# CM41x_M4 register map
Vendor: Analog Devices; Series: CM41x_M4; File version: 1p0
CPU: CM4 r0p1, little endian, MPU, FPU, 4 interrupt priority bits
Registers are 32-bit, read-write, reset 0x0 unless marked. A register's access mark holds for its fields unless they carry their own. Offsets are from the block's base; [hi:lo] are bit positions; lines under a group give offsets from that group; {n}, {i} and the like mark numbered series; 'fields as' and 'values as' point back to an identical list.

## SEC1 — System Event Controller
Base 0x40010000
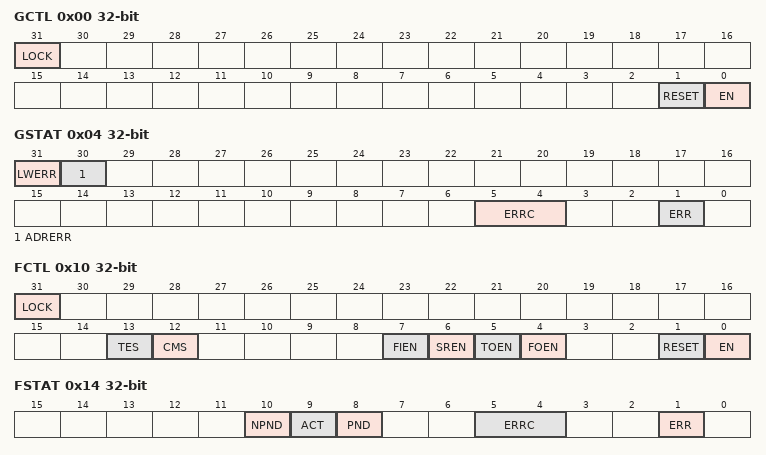
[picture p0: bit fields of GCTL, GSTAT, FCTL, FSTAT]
0x00 GCTL — Global Control Register
  [31] LOCK
    0=UNLOCK; 1=LOCK
  [1] RESET
    0=NO_RESET (No Action); 1=RESET
  [0] EN — Enable
    0=DIS (Disable); 1=EN (Enable)
0x04 GSTAT — Global Status Register
  [31] LWERR — Lock Write Error
    0=NO_LWERR (No Error); 1=LWERR (Error Occurred)
  [30] ADRERR — Address Error
    0=NO_ADRERR (No Error); 1=ADRERR (Error Occurred)
  [5:4] ERRC ro — Error Cause
    0=SFIERR (SFI Error); 2=SSIERR (SSI Error)
  [1] ERR — Error
    0=NO_ERR (No Error); 1=ERR (Error Occurred)
0x08 RAISE — Global Raise Register
  [7:0] SID range 0x00000000..0x000000FF — Source ID
0x10 FCTL — Fault Control Register
  [31] LOCK
    0=UNLOCK; 1=LOCK
  [13] TES — Trigger Event Select
    0=FLTACT_MODE (Fault Active Mode); 1=FLTPND_MODE (Fault Pending Mode)
  [12] CMS — COP Mode Select
    0=FLT_MODE (Fault Mode); 1=COP_MODE
  [7] FIEN — Fault Input Enable
    0=FLTIN_DIS (Disable); 1=FLTIN_EN (Enable)
  [6] SREN — System Reset Enable
    0=SYSRST_DIS (Disable); 1=SYSRST_EN (Enable)
  [5] TOEN — Trigger Output Enable
    0=TRGOUT_DIS (Disable); 1=TRGOUT_EN (Enable)
  [4] FOEN — Fault Output Enable
    0=FLTOUT_DIS (Disable); 1=FLTOUT_EN (Enable)
  [1] RESET
    0=NO_RESET (No Action); 1=RESET
  [0] EN — Enable
    0=DIS (Disable); 1=EN (Enable)
0x14 FSTAT — Fault Status Register
  [10] NPND ro — Next Pending Fault
    0=NO_NXTFLT (Not Pending); 1=NXTFLT (Pending)
  [9] ACT ro — Fault Active
    0=NO_FLTACT (No Fault); 1=FLTACT (Active Fault)
  [8] PND ro — Pending Fault
    0=NO_FLTPND (Not Pending); 1=FLTPND (Pending)
  [5:4] ERRC ro — Error Cause
    0=SOVFERR (Source Overflow Error); 2=ENDERR (End Error)
  [1] ERR — Error
    0=NO_ERR (No Error); 1=ERR (Error Occurred)
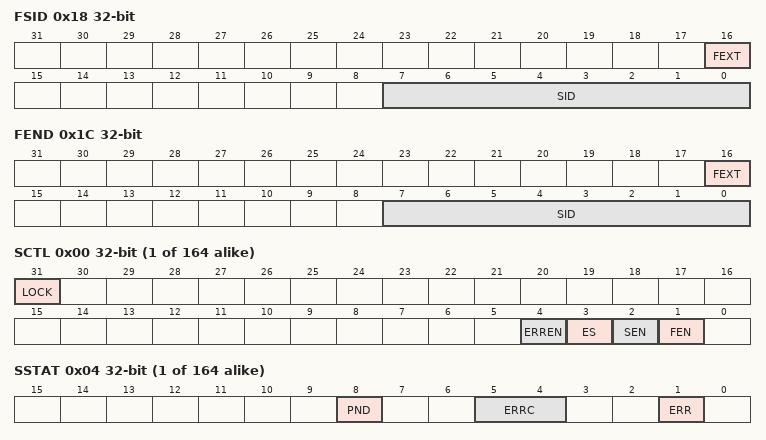
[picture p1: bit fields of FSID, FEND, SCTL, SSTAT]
0x18 FSID — Fault Source ID Register
  [16] FEXT ro — Fault External
    0=SRC_INTFLT (Fault Internal); 1=SRC_EXTFLT (Fault External)
  [7:0] SID ro — Source ID
0x1C FEND — Fault End Register
  [16] FEXT — Fault External
    0=END_INTFLT (Fault Internal); 1=END_EXTFLT (Fault External)
  [7:0] SID range 0x00000000..0x000000FF — Source ID
0x20 FDLY — Fault Delay Register
  [31:0] COUNT range 0x00000000..0xFFFFFFFF — Fault Delay
0x24 FDLY_CUR — Fault Delay Current Register
  [31:0] COUNT ro — Fault Delay
0x28 FSRDLY — Fault System Reset Delay Register
  [31:0] COUNT range 0x00000000..0xFFFFFFFF — Fault System Reset Delay
0x2C FSRDLY_CUR — Fault System Reset Delay Current Register
  [31:0] COUNT ro — Fault System Reset Delay
0x30 FCOPP — Fault COP Period Register
  [31:0] COUNT range 0x00000000..0xFFFFFFFF — Fault COP Period
0x34 FCOPP_CUR — Fault COP Period Current Register
  [31:0] COUNT ro — Fault COP Period
{0x800+8i} SEC1_SB[{i}] (i=0..163) group — SSI Registers
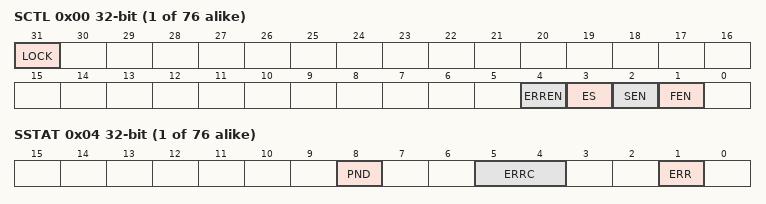
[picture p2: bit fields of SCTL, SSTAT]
  0x00 SCTL — Source Control Register n
    [31] LOCK
      0=UNLOCK; 1=LOCK
    [4] ERREN — Error Enable
      0=ERR_DIS (Disable); 1=ERR_EN (Enable)
    [3] ES — Edge Select
      0=LEVEL (Level Sensitive); 1=EDGE (Edge Sensitive)
    [2] SEN — Source (signal) Enable
      0=SRC_DIS (Disable); 1=SRC_EN (Enable)
    [1] FEN — Fault Enable
      0=FAULT_DIS (Disable); 1=FAULT_EN (Enable)
  0x04 SSTAT — Source Status Register n
    [8] PND — Pending Source
      0=NOTPENDING; 1=PENDING
    [5:4] ERRC ro — Error Cause
      0=SOVFERR (Source Overflow Error); 2=ENDERR (End Error)
    [1] ERR — Error
      0=NO_ERR (No Error); 1=ERR (Error Occurred)

## SEC0 — System Event Controller
Base 0x41004000
Registers as SEC1, without SEC1_SB[*]; these are added or differ:
{0x800+8i} SEC0_SB[{i}] (i=0..75) group — SSI Registers
  0x00 SCTL — Source Control Register n
    fields as SEC1.SEC1_SB[0].SCTL
  0x04 SSTAT — Source Status Register n
    fields as SEC1.SEC1_SB[0].SSTAT
